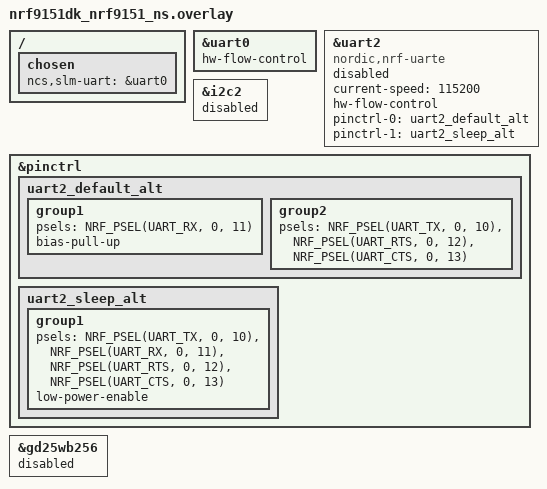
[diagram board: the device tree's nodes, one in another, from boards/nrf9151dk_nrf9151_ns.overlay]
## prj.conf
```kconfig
#
# Copyright (c) 2020 Nordic Semiconductor ASA
#
# SPDX-License-Identifier: LicenseRef-Nordic-5-Clause
#
# General config
CONFIG_LOG=y
CONFIG_ASSERT=y
CONFIG_ASSERT_VERBOSE=n
CONFIG_LOG_DEFAULT_LEVEL=3
CONFIG_STACK_SENTINEL=y
CONFIG_PICOLIBC_IO_FLOAT=y
CONFIG_RING_BUFFER=y
CONFIG_REBOOT=y
CONFIG_EVENTFD=y

# Segger RTT
CONFIG_USE_SEGGER_RTT=y
# Where console messages (printk) are output.
# By itself, SLM does not output any.
CONFIG_RTT_CONSOLE=y
CONFIG_UART_CONSOLE=n
# Where SLM logs are output.
CONFIG_LOG_BACKEND_RTT=y
CONFIG_LOG_BACKEND_UART=n
# Increase the buffer so that all SLM boot logs fit into the buffer.
# Because J-Link RTT Viewer has to be connected after the bootup,
# only logs that fit into the buffer are shown. This is especially useful in showing
# errors if SLM does not start properly.
CONFIG_SEGGER_RTT_BUFFER_SIZE_UP=2048

# Network
CONFIG_NETWORKING=y
CONFIG_NET_SOCKETS=y
CONFIG_NET_NATIVE=n
CONFIG_NET_IPV4=y
CONFIG_NET_IPV6=y

# Modem library
CONFIG_NRF_MODEM_LIB=y
CONFIG_AT_CMD_CUSTOM=y
# Align the max FD entry to NRF_MODEM_MAX_SOCKET_COUNT(8)
CONFIG_ZVFS_OPEN_MAX=8

# Handle modem fault
CONFIG_NRF_MODEM_LIB_ON_FAULT_APPLICATION_SPECIFIC=y

# Use GPIO
CONFIG_GPIO=y
CONFIG_GPIO_NRFX=y

# UART interface
CONFIG_SERIAL=y
CONFIG_UART_USE_RUNTIME_CONFIGURE=y
CONFIG_UART_ASYNC_API=y
CONFIG_NRFX_TIMER2=y

# Stacks and heaps
CONFIG_MAIN_STACK_SIZE=4096
CONFIG_HEAP_MEM_POOL_SIZE=16384
CONFIG_SYSTEM_WORKQUEUE_STACK_SIZE=4096
CONFIG_AT_MONITOR_HEAP_SIZE=4096

# Device power management
CONFIG_PM_DEVICE=y

# FOTA
CONFIG_HTTP_PARSER_URL=y
CONFIG_FOTA_DOWNLOAD=y
CONFIG_FOTA_DOWNLOAD_PROGRESS_EVT=y
CONFIG_DFU_TARGET=y
CONFIG_DOWNLOADER=y
CONFIG_DOWNLOADER_STACK_SIZE=4096
CONFIG_DOWNLOADER_MAX_FILENAME_SIZE=2048
CONFIG_BOOTLOADER_MCUBOOT=y
CONFIG_IMG_MANAGER=y

# FLASH
CONFIG_FLASH=y
CONFIG_FLASH_PAGE_LAYOUT=y
CONFIG_FLASH_MAP=y
CONFIG_STREAM_FLASH=y
CONFIG_MPU_ALLOW_FLASH_WRITE=y
CONFIG_IMG_ERASE_PROGRESSIVELY=y

# Settings
CONFIG_SETTINGS=y
CONFIG_SETTINGS_NVS=y
CONFIG_NVS=y

# nRF Cloud
CONFIG_NRF_CLOUD=y
CONFIG_NRF_CLOUD_MQTT=y
CONFIG_NRF_CLOUD_FOTA=n
CONFIG_NRF_CLOUD_AGNSS=y
CONFIG_NRF_CLOUD_AGNSS_FILTERED=n
CONFIG_NRF_CLOUD_PGPS=n
CONFIG_NRF_CLOUD_LOCATION=y
CONFIG_NRF_CLOUD_LOG_LEVEL_INF=y
CONFIG_NRF_CLOUD_GPS_LOG_LEVEL_INF=y
CONFIG_NRF_CLOUD_CLIENT_ID_SRC_INTERNAL_UUID=y
CONFIG_NRF_CLOUD_WIFI_LOCATION_ENCODE_OPT_MAC_RSSI=y
CONFIG_DATE_TIME=y
CONFIG_MODEM_INFO=y
CONFIG_MODEM_INFO_ADD_DATE_TIME=n

# UUID and JWT
CONFIG_MODEM_JWT=y

# MQTT client
#CONFIG_MQTT_KEEPALIVE=60
CONFIG_MQTT_CLEAN_SESSION=y

# AT command helper libraries
CONFIG_AT_PARSER=y
CONFIG_AT_MONITOR=y

# Eventfd's to use with AT-commands.
CONFIG_ZVFS_EVENTFD_MAX=2

# Disable TF-M logging.
# TF-M log sending will block until remote end is ready, when HWFC is used on UART1.
CONFIG_TFM_LOG_LEVEL_SILENCE=y

#
# SLM-specific configurations
#
CONFIG_SLM_CUSTOMER_VERSION=""
CONFIG_SLM_EXTERNAL_XTAL=n

# debug options
#CONFIG_LOG_BUFFER_SIZE=16384
CONFIG_SLM_LOG_LEVEL_DBG=y
#CONFIG_LOG_PRINTK=n
#CONFIG_LOG_MODE_IMMEDIATE=y

# For using external GNSS antenna
#CONFIG_MODEM_ANTENNA=y
#CONFIG_MODEM_ANTENNA_GNSS_EXTERNAL=y
```

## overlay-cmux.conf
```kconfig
#
# Copyright (c) 2023 Nordic Semiconductor ASA
#
# SPDX-License-Identifier: LicenseRef-Nordic-5-Clause
#

CONFIG_SLM_CMUX=y
CONFIG_SLM_SKIP_READY_MSG=y

# Zephyr modem subsystem
CONFIG_MODEM_MODULES=y
CONFIG_MODEM_CMUX=y

# Enable SLM UART backend
CONFIG_MODEM_BACKEND_UART=n
CONFIG_MODEM_BACKEND_UART_ASYNC=n
CONFIG_MODEM_BACKEND_UART_SLM=y
CONFIG_MODEM_BACKEND_UART_SLM_TRANSMIT_TIMEOUT_MS=1000

# These buffers are unused after AT#CMUX is enabled
# so use minimal buffer size
CONFIG_SLM_UART_RX_BUF_COUNT=2
CONFIG_SLM_UART_RX_BUF_SIZE=128
CONFIG_SLM_UART_TX_BUF_SIZE=128

# Following from Markus
CONFIG_MODEM_CMUX_WORK_BUFFER_SIZE=536
CONFIG_SLM_CMUX_UART_BUFFER_SIZE=6000
CONFIG_MODEM_CMUX_MTU=127

# debug options
#CONFIG_MODEM_CMUX_LOG_LEVEL_DBG=y
#CONFIG_MODEM_MODULES_LOG_LEVEL_DBG=y
```

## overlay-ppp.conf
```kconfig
#
# Copyright (c) 2023 Nordic Semiconductor ASA
#
# SPDX-License-Identifier: LicenseRef-Nordic-5-Clause
#

CONFIG_SLM_PPP=y

# When using PPP, disable commands of IP-based protocols to save flash space.
CONFIG_SLM_FTPC=n
CONFIG_SLM_TFTPC=n
CONFIG_SLM_HTTPC=n
CONFIG_SLM_MQTTC=n

#dect sink usage we do not need these
CONFIG_SLM_NRF_CLOUD=n
CONFIG_SLM_GNSS=n
CONFIG_SLM_SMS=n
CONFIG_SLM_FTPC=n
CONFIG_SLM_MQTTC=n
CONFIG_SLM_CARRIER=n
CONFIG_LWM2M_CARRIER_SETTINGS=n
CONFIG_SLM_TWI=n

# NCS modem libraries
CONFIG_PDN=y
CONFIG_AT_CMD_CUSTOM=y

CONFIG_NRF_MODEM_LIB_SHMEM_TX_SIZE=22528

# Zephyr PPP support
CONFIG_NET_NATIVE=y
CONFIG_NET_L2_PPP=y
CONFIG_MODEM_MODULES=y
CONFIG_MODEM_PPP=y

# Enable SLM UART backend
CONFIG_MODEM_BACKEND_UART=n
CONFIG_MODEM_BACKEND_UART_ASYNC=n
CONFIG_MODEM_BACKEND_UART_SLM=y
CONFIG_MODEM_BACKEND_UART_SLM_TRANSMIT_TIMEOUT_MS=1000

# L2 protocol
CONFIG_NET_L2_PPP_MGMT=y
CONFIG_NET_L2_PPP_OPTION_MRU=y
CONFIG_NET_L2_PPP_OPTION_SERVE_IP=y
CONFIG_NET_L2_PPP_OPTION_SERVE_DNS=y
CONFIG_NET_L2_PPP_TIMEOUT=5000
CONFIG_NET_L2_PPP_MAX_CONFIGURE_REQ_RETRANSMITS=20

# IP stack
CONFIG_NET_IP_ADDR_CHECK=n
CONFIG_NET_SOCKETS_PACKET=y
CONFIG_NET_IF_MAX_IPV6_COUNT=2
CONFIG_NET_IF_MAX_IPV4_COUNT=2

# network buffering
CONFIG_NET_BUF=y
CONFIG_NET_BUF_POOL_USAGE=y
CONFIG_NET_PKT_RX_COUNT=44
CONFIG_NET_BUF_RX_COUNT=88
CONFIG_NET_PKT_TX_COUNT=44
CONFIG_NET_BUF_TX_COUNT=88
CONFIG_NET_TC_RX_COUNT=0
CONFIG_NET_CONN_PACKET_CLONE_TIMEOUT=1000

# debug options
#CONFIG_LOG_PROCESS_THREAD_STACK_SIZE=4096
CONFIG_NET_LOG=y
#CONFIG_NET_IF_LOG_LEVEL_DBG=y
#CONFIG_NET_PKT_LOG_LEVEL_DBG=y
#CONFIG_NET_L2_PPP_LOG_LEVEL_DBG=y
#CONFIG_NET_MGMT_EVENT_LOG_LEVEL_DBG=y
#CONFIG_MODEM_MODULES_LOG_LEVEL_DBG=y
#CONFIG_UART_LOG_LEVEL_DBG=y
```

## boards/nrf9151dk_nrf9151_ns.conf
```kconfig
#
# Copyright (c) 2024 Nordic Semiconductor ASA
#
# SPDX-License-Identifier: LicenseRef-Nordic-5-Clause
#

# Configuration file for nRF9151DK.
# This file is merged with prj.conf in the application folder, and options
# set here will take precedence if they are present in both files.

# When working with PC terminal, unmask the following config.
#CONFIG_SLM_POWER_PIN=8
#CONFIG_SLM_INDICATE_PIN=0

# When working with external MCU, unmask the following config.
CONFIG_SLM_POWER_PIN=31
CONFIG_SLM_INDICATE_PIN=30
```

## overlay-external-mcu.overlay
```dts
/*
 * Copyright (c) 2024 Nordic Semiconductor ASA
 *
 * SPDX-License-Identifier: LicenseRef-Nordic-5-Clause
 */

/ {
	chosen {
		ncs,slm-uart = &uart2;
	};
};

&uart2 {
	status = "okay";
	current-speed = <1000000>;
};

/* uart0 is not needed if no logging is received there. */
&uart0 {
	status = "disabled";
};
```

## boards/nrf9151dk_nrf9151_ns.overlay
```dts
/*
 * Copyright (c) 2024 Nordic Semiconductor ASA
 *
 * SPDX-License-Identifier: LicenseRef-Nordic-5-Clause
 */

 / {
	chosen {
		ncs,slm-uart = &uart0;
	};
};

&uart0 {
	status = "okay";
	hw-flow-control;
};

&uart2 {
	compatible = "nordic,nrf-uarte";
	current-speed = <115200>;
	status = "disabled";
	hw-flow-control;

	pinctrl-0 = <&uart2_default_alt>;
	pinctrl-1 = <&uart2_sleep_alt>;
	pinctrl-names = "default", "sleep";
};

&i2c2 {
	status = "disabled";
};

&pinctrl {
	uart2_default_alt: uart2_default_alt {
		group1 {
			psels = <NRF_PSEL(UART_RX, 0, 11)>;
			bias-pull-up;
		};
		group2 {
			psels = <NRF_PSEL(UART_TX, 0, 10)>,
				<NRF_PSEL(UART_RTS, 0, 12)>,
				<NRF_PSEL(UART_CTS, 0, 13)>;
		};
	};

	uart2_sleep_alt: uart2_sleep_alt {
		group1 {
			psels = <NRF_PSEL(UART_TX, 0, 10)>,
				<NRF_PSEL(UART_RX, 0, 11)>,
				<NRF_PSEL(UART_RTS, 0, 12)>,
				<NRF_PSEL(UART_CTS, 0, 13)>;
			low-power-enable;
		};
	};
};

/* Enable external flash */
&gd25wb256 {
	status = "disabled";
};
/* Just for sure to disable as these are in 30/31 pins where pwr pin is */
arduino_i2c: &i2c2 {
	status = "disabled";
};
```

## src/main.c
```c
/*
 * Copyright (c) 2019 Nordic Semiconductor ASA
 *
 * SPDX-License-Identifier: LicenseRef-Nordic-5-Clause
 */
#include <zephyr/logging/log.h>
#include <zephyr/kernel.h>
#include <nrf_modem.h>
#include <hal/nrf_power.h>
#include <modem/nrf_modem_lib.h>
#include <zephyr/dfu/mcuboot.h>
#include <dfu/dfu_target.h>
#include <zephyr/sys/reboot.h>
#include <net/fota_download.h>
#include "slm_at_host.h"
#include "slm_at_fota.h"
#include "slm_settings.h"
#include "slm_util.h"
#include "slm_ctrl_pin.h"

LOG_MODULE_REGISTER(slm, CONFIG_SLM_LOG_LEVEL);

#define SLM_WQ_STACK_SIZE	KB(4)
#define SLM_WQ_PRIORITY		K_LOWEST_APPLICATION_THREAD_PRIO
static K_THREAD_STACK_DEFINE(slm_wq_stack_area, SLM_WQ_STACK_SIZE);

struct k_work_q slm_work_q;

NRF_MODEM_LIB_ON_INIT(lwm2m_init_hook, on_modem_lib_init, NULL);
NRF_MODEM_LIB_ON_DFU_RES(main_dfu_hook, on_modem_dfu_res, NULL);

static void on_modem_lib_init(int ret, void *ctx)
{
	ARG_UNUSED(ctx);

	/** ret: Zero on success, a positive value @em nrf_modem_dfu when executing
	 *  Modem firmware updates, and negative errno on other failures.
	 */
	LOG_INF("lib_modem init: %d", ret);
}

#if defined(CONFIG_NRF_MODEM_LIB_ON_FAULT_APPLICATION_SPECIFIC)
static struct nrf_modem_fault_info modem_fault_info;

static void on_modem_failure(struct k_work *)
{
	int ret;

	rsp_send("\r\n#XMODEM: FAULT,0x%x,0x%x\r\n", modem_fault_info.reason,
		 modem_fault_info.program_counter);

	ret = nrf_modem_lib_shutdown();
	rsp_send("\r\n#XMODEM: SHUTDOWN,%d\r\n", ret);

	ret = nrf_modem_lib_init();
	rsp_send("\r\n#XMODEM: INIT,%d\r\n", ret);
}
K_WORK_DEFINE(modem_failure_work, on_modem_failure);

void nrf_modem_fault_handler(struct nrf_modem_fault_info *fault_info)
{
	modem_fault_info = *fault_info;

	k_work_submit(&modem_failure_work);
}
#endif /* CONFIG_NRF_MODEM_LIB_ON_FAULT_APPLICATION_SPECIFIC */

static void on_modem_dfu_res(int dfu_res, void *ctx)
{
	slm_fota_type = DFU_TARGET_IMAGE_TYPE_MODEM_DELTA;
	slm_fota_stage = FOTA_STAGE_COMPLETE;
	slm_fota_status = FOTA_STATUS_ERROR;
	slm_fota_info = dfu_res;

	switch (dfu_res) {
	case NRF_MODEM_DFU_RESULT_OK:
		LOG_INF("Modem update OK. Running new firmware.");
		slm_fota_status = FOTA_STATUS_OK;
		slm_fota_info = 0;
		break;
	case NRF_MODEM_DFU_RESULT_UUID_ERROR:
	case NRF_MODEM_DFU_RESULT_AUTH_ERROR:
		LOG_ERR("Modem update failed (0x%x). Running old firmware.", dfu_res);
		break;
	case NRF_MODEM_DFU_RESULT_HARDWARE_ERROR:
	case NRF_MODEM_DFU_RESULT_INTERNAL_ERROR:
		LOG_ERR("Fatal error (0x%x) encountered during modem update.", dfu_res);
		break;
	case NRF_MODEM_DFU_RESULT_VOLTAGE_LOW:
		LOG_ERR("Modem update postponed due to low voltage. "
			"Reset the modem once you have sufficient power.");
		slm_fota_stage = FOTA_STAGE_ACTIVATE;
		break;
	default:
		LOG_ERR("Unhandled nrf_modem DFU result code 0x%x.", dfu_res);
		break;
	}
}

static void check_app_fota_status(void)
{
	/** When a TEST image is swapped to primary partition and booted by MCUBOOT,
	 * the API mcuboot_swap_type() will return BOOT_SWAP_TYPE_REVERT. By this type
	 * MCUBOOT means that the TEST image is booted OK and, if it's not confirmed
	 * next, it'll be swapped back to secondary partition and original application
	 * image will be restored to the primary partition (so-called Revert).
	 */
	const int type = mcuboot_swap_type();

	switch (type) {
	/** Attempt to boot the contents of slot 0. */
	case BOOT_SWAP_TYPE_NONE:
		/* Normal reset, nothing happened, do nothing. */
		return;
	/** Swap to slot 1. Absent a confirm command, revert back on next boot. */
	case BOOT_SWAP_TYPE_TEST:
	/** Swap to slot 1, and permanently switch to booting its contents. */
	case BOOT_SWAP_TYPE_PERM:
	/** Swap failed because image to be run is not valid. */
	case BOOT_SWAP_TYPE_FAIL:
		slm_fota_status = FOTA_STATUS_ERROR;
		slm_fota_info = type;
		break;
	/** Swap back to alternate slot. A confirm changes this state to NONE. */
	case BOOT_SWAP_TYPE_REVERT:
		/* Happens on a successful application FOTA. */
		const int ret = boot_write_img_confirmed();

		slm_fota_info = ret;
		slm_fota_status = ret ? FOTA_STATUS_ERROR : FOTA_STATUS_OK;
		break;
	}
	slm_fota_type = DFU_TARGET_IMAGE_TYPE_MCUBOOT;
	slm_fota_stage = FOTA_STAGE_COMPLETE;
}

int lte_auto_connect(void)
{
	int err = 0;
#if defined(CONFIG_SLM_AUTO_CONNECT)
	int ret;
	int n;
	int stat;
	struct network_config {
		/* Refer to AT command manual of %XSYSTEMMODE for system mode settings */
		int lte_m_support;     /* 0 ~ 1 */
		int nb_iot_support;    /* 0 ~ 1 */
		int gnss_support;      /* 0 ~ 1 */
		int lte_preference;    /* 0 ~ 4 */
		/* Refer to AT command manual of +CGDCONT and +CGAUTH for PDN configuration */
		bool pdp_config;       /* PDP context definition required or not */
		char *pdn_fam;         /* PDP type: "IP", "IPV6", "IPV4V6", "Non-IP" */
		char *pdn_apn;         /* Access point name */
		int pdn_auth;          /* PDN authentication protocol 0(None), 1(PAP), 2(CHAP) */
		char *pdn_username;    /* PDN connection authentication username */
		char *pdn_password;    /* PDN connection authentication password */
	};
	const struct network_config cfg = {
#include "slm_auto_connect.h"
	};

	ret = slm_util_at_scanf("AT+CEREG?", "+CEREG: %d,%d", &n, &stat);
	if (ret != 2 || (stat == 1 || stat == 5)) {
		return 0;
	}

	LOG_INF("lte auto connect");
	err = slm_util_at_printf("AT%%XSYSTEMMODE=%d,%d,%d,%d", cfg.lte_m_support,
				  cfg.nb_iot_support, cfg.gnss_support, cfg.lte_preference);
	if (err) {
		LOG_ERR("Failed to configure system mode: %d", err);
		return err;
	}
	if (cfg.pdp_config) {
		err = slm_util_at_printf("AT+CGDCONT=0,%s,%s", cfg.pdn_fam, cfg.pdn_apn);
		if (err) {
			LOG_ERR("Failed to configure PDN: %d", err);
			return err;
		}
	}
	if (cfg.pdp_config && cfg.pdn_auth != 0) {
		err = slm_util_at_printf("AT+CGAUTH=0,%d,%s,%s", cfg.pdn_auth,
					  cfg.pdn_username, cfg.pdn_password);
		if (err) {
			LOG_ERR("Failed to configure AUTH: %d", err);
			return err;
		}
	}
	err = slm_util_at_printf("AT+CFUN=1");
	if (err) {
		LOG_ERR("Failed to turn on radio: %d", err);
		return err;
	}
#endif /* CONFIG_SLM_AUTO_CONNECT */

	return err;
}

int start_execute(void)
{
	int err;

	LOG_INF("Serial LTE Modem");

	slm_ctrl_pin_init();

	/* This will send "READY" or "INIT ERROR" to UART so after this nothing
	 * should be done that can fail
	 */
	err = slm_at_host_init();
	if (err) {
		LOG_ERR("Failed to init at_host: %d", err);
		return err;
	}

	k_work_queue_start(&slm_work_q, slm_wq_stack_area,
			   K_THREAD_STACK_SIZEOF(slm_wq_stack_area),
			   SLM_WQ_PRIORITY, NULL);
	(void)lte_auto_connect();

	return 0;
}

int main(void)
{
	const uint32_t rr = nrf_power_resetreas_get(NRF_POWER_NS);

	nrf_power_resetreas_clear(NRF_POWER_NS, 0x70017);
	LOG_DBG("RR: 0x%08x", rr);

	slm_ctrl_pin_init_gpios();

	/* Init and load settings */
	if (slm_settings_init() != 0) {
		LOG_WRN("Failed to init slm settings");
	}

#if defined(CONFIG_SLM_FULL_FOTA)
	if (slm_modem_full_fota) {
		slm_finish_modem_full_fota();
		slm_fota_type = DFU_TARGET_IMAGE_TYPE_FULL_MODEM;
	}
#endif

	int ret = nrf_modem_lib_init();

	if (ret) {
		LOG_ERR("Modem library init failed, err: %d", ret);
		if (ret != -EAGAIN && ret != -EIO) {
			goto exit;
		} else if (ret == -EIO) {
			LOG_ERR("Please program full modem firmware with the bootloader or "
				"external tools");
		}
	}

	check_app_fota_status();

#if defined(CONFIG_SLM_START_SLEEP)

	if (!(rr & NRF_POWER_RESETREAS_OFF_MASK)) { /* DETECT signal from GPIO */

		slm_ctrl_pin_enter_sleep_no_uninit();
	}
#endif /* CONFIG_SLM_START_SLEEP */

	ret = start_execute();
exit:
	if (ret) {
		LOG_ERR("Failed to start SLM (%d). It's not operational!!!", ret);
	}
	return ret;
}
/***** START OF INTERNAL CHANGE. DO NOT COMMIT TO NCS MASTER. *****/
#include <zephyr/init.h>
#include <nrf.h>
#include <hal/nrf_gpio.h>

static int modem_trace_enable(void)
{
	/* GPIO configurations for trace and debug */
	#define CS_PIN_CFG_TRACE_CLK	21 //GPIO_OUT_PIN21_Pos
	#define CS_PIN_CFG_TRACE_DATA0	22 //GPIO_OUT_PIN22_Pos
	#define CS_PIN_CFG_TRACE_DATA1	23 //GPIO_OUT_PIN23_Pos
	#define CS_PIN_CFG_TRACE_DATA2	24 //GPIO_OUT_PIN24_Pos
	#define CS_PIN_CFG_TRACE_DATA3	25 //GPIO_OUT_PIN25_Pos

	// Configure outputs.
	// CS_PIN_CFG_TRACE_CLK
	NRF_P0_NS->PIN_CNF[CS_PIN_CFG_TRACE_CLK] = (GPIO_PIN_CNF_DRIVE_H0H1 << GPIO_PIN_CNF_DRIVE_Pos) |
		(GPIO_PIN_CNF_INPUT_Disconnect << GPIO_PIN_CNF_INPUT_Pos);

	// CS_PIN_CFG_TRACE_DATA0
	NRF_P0_NS->PIN_CNF[CS_PIN_CFG_TRACE_DATA0] = (GPIO_PIN_CNF_DRIVE_H0H1 << GPIO_PIN_CNF_DRIVE_Pos) |
		(GPIO_PIN_CNF_INPUT_Disconnect << GPIO_PIN_CNF_INPUT_Pos);

	// CS_PIN_CFG_TRACE_DATA1
	NRF_P0_NS->PIN_CNF[CS_PIN_CFG_TRACE_DATA1] = (GPIO_PIN_CNF_DRIVE_H0H1 << GPIO_PIN_CNF_DRIVE_Pos) |
		(GPIO_PIN_CNF_INPUT_Disconnect << GPIO_PIN_CNF_INPUT_Pos);

	// CS_PIN_CFG_TRACE_DATA2
	NRF_P0_NS->PIN_CNF[CS_PIN_CFG_TRACE_DATA2] = (GPIO_PIN_CNF_DRIVE_H0H1 << GPIO_PIN_CNF_DRIVE_Pos) |
		(GPIO_PIN_CNF_INPUT_Disconnect << GPIO_PIN_CNF_INPUT_Pos);

	// CS_PIN_CFG_TRACE_DATA3
	NRF_P0_NS->PIN_CNF[CS_PIN_CFG_TRACE_DATA3] = (GPIO_PIN_CNF_DRIVE_H0H1 << GPIO_PIN_CNF_DRIVE_Pos) |
		(GPIO_PIN_CNF_INPUT_Disconnect << GPIO_PIN_CNF_INPUT_Pos);

	NRF_P0_NS->DIR = 0xFFFFFFFF;

	return 0;
}

SYS_INIT(modem_trace_enable, PRE_KERNEL_1, 0);
/***** END OF INTERNAL CHANGE *****/
```
